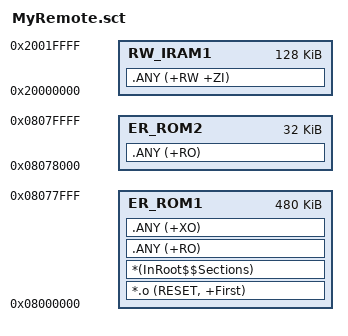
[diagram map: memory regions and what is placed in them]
; *************************************************************
; *** Scatter-Loading Description File generated by uVision ***
; *************************************************************

LR_ROM1 0x08000000 0x00078000  {    ; load region size_region
  ER_ROM1 0x08000000 0x00078000  {  ; load address = execution address
   *.o (RESET, +First)
   *(InRoot$$Sections)
   .ANY (+RO)
   .ANY (+XO)
  }
  RW_IRAM1 0x20000000 0x00020000  {  ; RW data
   .ANY (+RW +ZI)
  }
}

LR_ROM2 0x08078000 0x00008000  {
  ER_ROM2 0x08078000 0x00008000  {  ; load address = execution address
   .ANY (+RO)
  }
}
